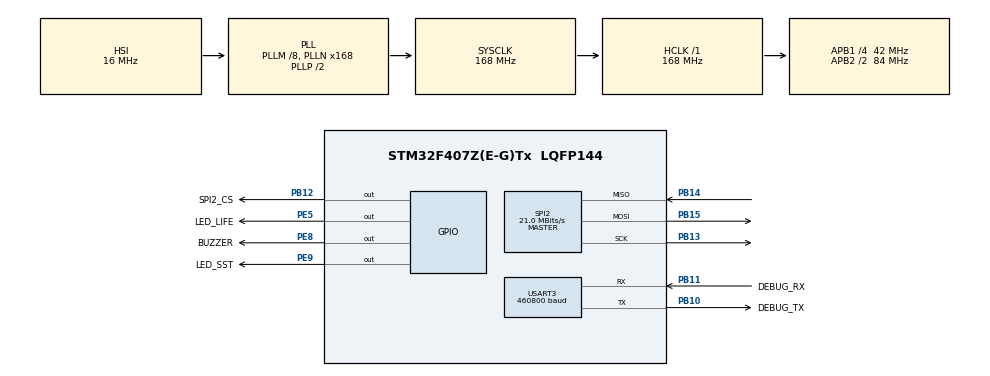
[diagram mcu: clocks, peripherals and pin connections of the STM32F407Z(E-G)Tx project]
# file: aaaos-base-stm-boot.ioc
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IWDG.Prescaler=IWDG_PRESCALER_256
Mcu.Family=STM32F4
Mcu.Name=STM32F407Z(E-G)Tx
Mcu.Package=LQFP144
NVIC.PriorityGroup=NVIC_PRIORITYGROUP_4
NVIC.USART3_IRQn=true\:10\:0\:true\:false\:true\:true\:true\:true
PB10.GPIO_Label=DEBUG_TX
PB10.Mode=Asynchronous
PB10.Signal=USART3_TX
PB11.GPIO_Label=DEBUG_RX
PB11.Mode=Asynchronous
PB11.Signal=USART3_RX
PB12.GPIO_Label=SPI2_CS
PB12.Signal=GPIO_Output
PB13.Mode=Full_Duplex_Master
PB13.Signal=SPI2_SCK
PB14.Mode=Full_Duplex_Master
PB14.Signal=SPI2_MISO
PB15.Mode=Full_Duplex_Master
PB15.Signal=SPI2_MOSI
PE5.GPIO_Label=LED_LIFE
PE5.PinState=GPIO_PIN_SET
PE5.Signal=GPIO_Output
PE8.GPIO_Label=BUZZER
PE8.Signal=GPIO_Output
PE9.GPIO_Label=LED_SST
PE9.Signal=GPIO_Output
ProjectManager.HeapSize=0x200
ProjectManager.StackSize=0x400
ProjectManager.TargetToolchain=STM32CubeIDE
RCC.48MHZClocksFreq_Value=48000000
RCC.AHBFreq_Value=168000000
RCC.APB1CLKDivider=RCC_HCLK_DIV4
RCC.APB1Freq_Value=42000000
RCC.APB1TimFreq_Value=84000000
RCC.APB2CLKDivider=RCC_HCLK_DIV2
RCC.APB2Freq_Value=84000000
RCC.APB2TimFreq_Value=168000000
RCC.CortexFreq_Value=168000000
RCC.HCLKFreq_Value=168000000
RCC.HSE_VALUE=25000000
RCC.HSI_VALUE=16000000
RCC.LSE_VALUE=32768
RCC.PLLM=8
RCC.PLLN=168
RCC.PLLQ=7
RCC.RCC_RTC_Clock_Source=RCC_RTCCLKSOURCE_LSE
RCC.RCC_RTC_Clock_SourceVirtual=RCC_RTCCLKSOURCE_LSE
RCC.SYSCLKFreq_VALUE=168000000
RCC.SYSCLKSource=RCC_SYSCLKSOURCE_PLLCLK
RCC.VCOOutputFreq_Value=336000000
SPI2.CalculateBaudRate=21.0 MBits/s
SPI2.Direction=SPI_DIRECTION_2LINES
SPI2.Mode=SPI_MODE_MASTER
SPI2.VirtualType=VM_MASTER
USART3.BaudRate=460800
USART3.VirtualMode=VM_ASYNC
VP_IWDG_VS_IWDG.Mode=IWDG_Activate
board=custom

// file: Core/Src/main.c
/* USER CODE BEGIN Header */
/**
  ******************************************************************************
  * @file           : main.c
  * @brief          : Main program body
  ******************************************************************************
  * @attention
  *
  * Copyright (c) 2022 STMicroelectronics.
  * All rights reserved.
  *
  * This software is licensed under terms that can be found in the LICENSE file
  * in the root directory of this software component.
  * If no LICENSE file comes with this software, it is provided AS-IS.
  *
  ******************************************************************************
  */
/* USER CODE END Header */
#include "main.h"
#include "iwdg.h"
#include "spi.h"
#include "usart.h"
#include "gpio.h"

/* USER CODE BEGIN Includes */
#include "boot.h"
/* USER CODE END Includes */

void SystemClock_Config(void);

int main(void)
{

  /* MCU Configuration--------------------------------------------------------*/

  /* Reset of all peripherals, Initializes the Flash interface and the Systick. */
  HAL_Init();

  /* Configure the system clock */
  SystemClock_Config();

  /* Initialize all configured peripherals */
  MX_GPIO_Init();
  MX_USART3_UART_Init();
  MX_SPI2_Init();
  MX_IWDG_Init();
  /* USER CODE BEGIN 2 */
  boot_main();
  /* USER CODE END 2 */

  /* Infinite loop */
  while (1)
  {

  }
}

void SystemClock_Config(void)
{
  RCC_OscInitTypeDef RCC_OscInitStruct = {0};
  RCC_ClkInitTypeDef RCC_ClkInitStruct = {0};

  /** Configure the main internal regulator output voltage
  */
  __HAL_RCC_PWR_CLK_ENABLE();
  __HAL_PWR_VOLTAGESCALING_CONFIG(PWR_REGULATOR_VOLTAGE_SCALE1);

  /** Initializes the RCC Oscillators according to the specified parameters
  * in the RCC_OscInitTypeDef structure.
  */
  RCC_OscInitStruct.OscillatorType = RCC_OSCILLATORTYPE_HSI|RCC_OSCILLATORTYPE_LSI;
  RCC_OscInitStruct.HSIState = RCC_HSI_ON;
  RCC_OscInitStruct.HSICalibrationValue = RCC_HSICALIBRATION_DEFAULT;
  RCC_OscInitStruct.LSIState = RCC_LSI_ON;
  RCC_OscInitStruct.PLL.PLLState = RCC_PLL_ON;
  RCC_OscInitStruct.PLL.PLLSource = RCC_PLLSOURCE_HSI;
  RCC_OscInitStruct.PLL.PLLM = 8;
  RCC_OscInitStruct.PLL.PLLN = 168;
  RCC_OscInitStruct.PLL.PLLP = RCC_PLLP_DIV2;
  RCC_OscInitStruct.PLL.PLLQ = 7;
  if (HAL_RCC_OscConfig(&RCC_OscInitStruct) != HAL_OK)
  {
    Error_Handler();
  }

  /** Initializes the CPU, AHB and APB buses clocks
  */
  RCC_ClkInitStruct.ClockType = RCC_CLOCKTYPE_HCLK|RCC_CLOCKTYPE_SYSCLK
                              |RCC_CLOCKTYPE_PCLK1|RCC_CLOCKTYPE_PCLK2;
  RCC_ClkInitStruct.SYSCLKSource = RCC_SYSCLKSOURCE_PLLCLK;
  RCC_ClkInitStruct.AHBCLKDivider = RCC_SYSCLK_DIV1;
  RCC_ClkInitStruct.APB1CLKDivider = RCC_HCLK_DIV4;
  RCC_ClkInitStruct.APB2CLKDivider = RCC_HCLK_DIV2;

  if (HAL_RCC_ClockConfig(&RCC_ClkInitStruct, FLASH_LATENCY_5) != HAL_OK)
  {
    Error_Handler();
  }
}

void Error_Handler(void)
{
  __disable_irq();
  while (1)
  {
  }
}
